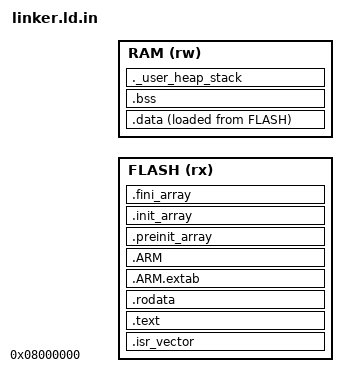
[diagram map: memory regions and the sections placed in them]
/* ==============================================================================
 * Universal STM32 Linker Script Template
 * Dynamic variables populated by CMake:
 *   @FLASH_SIZE@   - Size of Flash memory (e.g. 512K, 1024K, 0x80000)
 *   @RAM_SIZE@     - Size of RAM memory   (e.g. 96K, 128K, 0x18000)
 *   @RAM_ORIGIN@   - Origin of RAM memory (e.g. 0x20000000, 0x24000000)
 * ============================================================================== */

ENTRY(Reset_Handler)

/* Highest address of the user mode stack */
_estack = ORIGIN(RAM) + LENGTH(RAM);

/* Required minimum heap and stack reservations */
_min_heap_size  = 0x400; /* 1KB minimum reserved heap */
_min_stack_size = 0x800; /* 2KB minimum reserved stack */

MEMORY
{
  FLASH (rx) : ORIGIN = 0x08000000, LENGTH = @FLASH_SIZE@
  RAM   (rw) : ORIGIN = @RAM_ORIGIN@, LENGTH = @RAM_SIZE@
}

SECTIONS
{
  /* The vector table must be located at the beginning of Flash */
  .isr_vector :
  {
    . = ALIGN(4);
    KEEP(*(.isr_vector))
    . = ALIGN(4);
  } >FLASH

  /* Program code and constants */
  .text :
  {
    . = ALIGN(4);
    *(.text)
    *(.text*)
    *(.glue_7)
    *(.glue_7t)
    *(.eh_frame)

    KEEP(*(.init))
    KEEP(*(.fini))

    . = ALIGN(4);
    _etext = .;
  } >FLASH

  /* Constant read-only data */
  .rodata :
  {
    . = ALIGN(4);
    *(.rodata)
    *(.rodata*)
    . = ALIGN(4);
  } >FLASH

  /* ARM unwinding and exception handling */
  .ARM.extab :
  {
    . = ALIGN(4);
    *(.ARM.extab* .gnu.linkonce.armextab.*)
    . = ALIGN(4);
  } >FLASH

  .ARM :
  {
    . = ALIGN(4);
    __exidx_start = .;
    *(.ARM.exidx*)
    __exidx_end = .;
    . = ALIGN(4);
  } >FLASH

  /* Static constructor / destructor tables */
  .preinit_array :
  {
    . = ALIGN(4);
    PROVIDE_HIDDEN (__preinit_array_start = .);
    KEEP (*(.preinit_array*))
    PROVIDE_HIDDEN (__preinit_array_end = .);
    . = ALIGN(4);
  } >FLASH

  .init_array :
  {
    . = ALIGN(4);
    PROVIDE_HIDDEN (__init_array_start = .);
    KEEP (*(SORT(.init_array.*)))
    KEEP (*(.init_array*))
    PROVIDE_HIDDEN (__init_array_end = .);
    . = ALIGN(4);
  } >FLASH

  .fini_array :
  {
    . = ALIGN(4);
    PROVIDE_HIDDEN (__fini_array_start = .);
    KEEP (*(SORT(.fini_array.*)))
    KEEP (*(.fini_array*))
    PROVIDE_HIDDEN (__fini_array_end = .);
    . = ALIGN(4);
  } >FLASH

  /* Initialized data loaded from Flash into RAM */
  _sidata = LOADADDR(.data);

  .data :
  {
    . = ALIGN(4);
    _sdata = .;
    *(.data)
    *(.data*)
    . = ALIGN(4);
    _edata = .;
  } >RAM AT> FLASH

  /* Uninitialized data section, zero-cleared at startup */
  .bss :
  {
    . = ALIGN(4);
    _sbss = .;
    __bss_start__ = _sbss;
    *(.bss)
    *(.bss*)
    *(COMMON)
    . = ALIGN(4);
    _ebss = .;
    __bss_end__ = _ebss;
  } >RAM

  /* Memory check section to ensure RAM capacity fits heap + stack */
  ._user_heap_stack :
  {
    . = ALIGN(8);
    PROVIDE ( end = . );
    PROVIDE ( _end = . );
    . = . + _min_heap_size;
    . = . + _min_stack_size;
    . = ALIGN(8);
  } >RAM

  /* Discard standard library debug and runtime bloat if unneeded */
  /DISCARD/ :
  {
    libc.a ( * )
    libm.a ( * )
    libgcc.a ( * )
  }

  .ARM.attributes 0 : { *(.ARM.attributes) }
}
